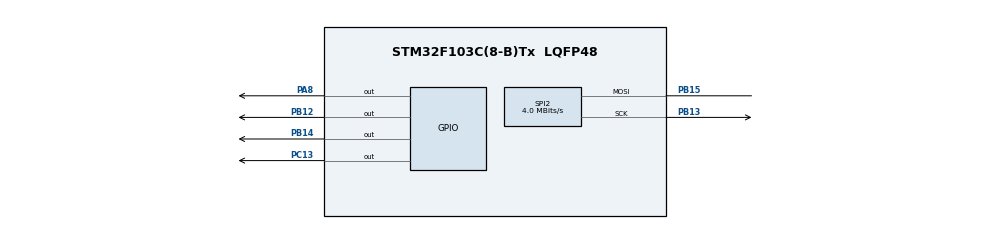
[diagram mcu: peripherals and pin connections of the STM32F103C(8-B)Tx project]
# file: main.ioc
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Mcu.Family=STM32F1
Mcu.Name=STM32F103C(8-B)Tx
Mcu.Package=LQFP48
NVIC.PriorityGroup=NVIC_PRIORITYGROUP_4
PA13.Mode=Serial_Wire
PA13.Signal=SYS_JTMS-SWDIO
PA14.Mode=Serial_Wire
PA14.Signal=SYS_JTCK-SWCLK
PA8.Signal=GPIO_Output
PB12.Signal=GPIO_Output
PB13.Mode=Simplex_Bidirectional_Master
PB13.Signal=SPI2_SCK
PB14.Signal=GPIO_Output
PB15.Mode=Simplex_Bidirectional_Master
PB15.Signal=SPI2_MOSI
PC13-TAMPER-RTC.Signal=GPIO_Output
ProjectManager.HeapSize=0x200
ProjectManager.StackSize=0x400
ProjectManager.TargetToolchain=Makefile
RCC.APB1Freq_Value=8000000
RCC.APB2Freq_Value=8000000
SPI2.BaudRatePrescaler=SPI_BAUDRATEPRESCALER_2
SPI2.CalculateBaudRate=4.0 MBits/s
SPI2.Direction=SPI_DIRECTION_1LINE
SPI2.Mode=SPI_MODE_MASTER
SPI2.VirtualType=VM_MASTER
board=main

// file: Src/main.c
#include "main.h"
#include "stm32f1xx_hal.h"

/* USER CODE BEGIN Includes */
#include "ssd1306_tests.h"
#include "ssd1306.h"
/* USER CODE END Includes */

SPI_HandleTypeDef hspi2;

/* USER CODE BEGIN PV */
/* Private variables ---------------------------------------------------------*/

/* USER CODE END PV */

void SystemClock_Config(void);
static void MX_GPIO_Init(void);
static void MX_SPI2_Init(void);

/* USER CODE BEGIN PFP */
/* Private function prototypes -----------------------------------------------*/

/* USER CODE END PFP */

/* USER CODE BEGIN 0 */
void init() {
    ssd1306_TestAll();

/*
    HAL_Delay(3000);

    for(uint8_t y = 0; y < 64; y++) {
        if(!(y&1)) { continue; }

        for(uint8_t x = 0; x < 128; x++) {
          ssd1306_DrawPixel(x, y, White);
        }
    }

    for(uint8_t x = 0; x < 128; x++) {
        if(!(x&1)) { continue; }

        for(uint8_t y = 0; y < 64; y++) {
          ssd1306_DrawPixel(x, y, White);
        }
    }

    ssd1306_UpdateScreen();
*/
}

void loop() {
    HAL_Delay(100);
}

/* USER CODE END 0 */

int main(void)
{

  /* MCU Configuration----------------------------------------------------------*/

  /* Reset of all peripherals, Initializes the Flash interface and the Systick. */
  HAL_Init();

  /* Configure the system clock */
  SystemClock_Config();

  /* Initialize all configured peripherals */
  MX_GPIO_Init();
  MX_SPI2_Init();

  /* Infinite loop */
  /* USER CODE BEGIN WHILE */
  init();
  while (1)
  {
    loop();
  /* USER CODE END WHILE */

  }

}

/** System Clock Configuration
*/
void SystemClock_Config(void)
{

  RCC_OscInitTypeDef RCC_OscInitStruct;
  RCC_ClkInitTypeDef RCC_ClkInitStruct;

    /**Initializes the CPU, AHB and APB busses clocks
    */
  RCC_OscInitStruct.OscillatorType = RCC_OSCILLATORTYPE_HSI;
  RCC_OscInitStruct.HSIState = RCC_HSI_ON;
  RCC_OscInitStruct.HSICalibrationValue = 16;
  RCC_OscInitStruct.PLL.PLLState = RCC_PLL_NONE;
  if (HAL_RCC_OscConfig(&RCC_OscInitStruct) != HAL_OK)
  {
    _Error_Handler(__FILE__, __LINE__);
  }

    /**Initializes the CPU, AHB and APB busses clocks
    */
  RCC_ClkInitStruct.ClockType = RCC_CLOCKTYPE_HCLK|RCC_CLOCKTYPE_SYSCLK
                              |RCC_CLOCKTYPE_PCLK1|RCC_CLOCKTYPE_PCLK2;
  RCC_ClkInitStruct.SYSCLKSource = RCC_SYSCLKSOURCE_HSI;
  RCC_ClkInitStruct.AHBCLKDivider = RCC_SYSCLK_DIV1;
  RCC_ClkInitStruct.APB1CLKDivider = RCC_HCLK_DIV1;
  RCC_ClkInitStruct.APB2CLKDivider = RCC_HCLK_DIV1;

  if (HAL_RCC_ClockConfig(&RCC_ClkInitStruct, FLASH_LATENCY_0) != HAL_OK)
  {
    _Error_Handler(__FILE__, __LINE__);
  }

    /**Configure the Systick interrupt time
    */
  HAL_SYSTICK_Config(HAL_RCC_GetHCLKFreq()/1000);

    /**Configure the Systick
    */
  HAL_SYSTICK_CLKSourceConfig(SYSTICK_CLKSOURCE_HCLK);

  /* SysTick_IRQn interrupt configuration */
  HAL_NVIC_SetPriority(SysTick_IRQn, 0, 0);
}

/* SPI2 init function */
static void MX_SPI2_Init(void)
{

  /* SPI2 parameter configuration*/
  hspi2.Instance = SPI2;
  hspi2.Init.Mode = SPI_MODE_MASTER;
  hspi2.Init.Direction = SPI_DIRECTION_1LINE;
  hspi2.Init.DataSize = SPI_DATASIZE_8BIT;
  hspi2.Init.CLKPolarity = SPI_POLARITY_LOW;
  hspi2.Init.CLKPhase = SPI_PHASE_1EDGE;
  hspi2.Init.NSS = SPI_NSS_SOFT;
  hspi2.Init.BaudRatePrescaler = SPI_BAUDRATEPRESCALER_2;
  hspi2.Init.FirstBit = SPI_FIRSTBIT_MSB;
  hspi2.Init.TIMode = SPI_TIMODE_DISABLE;
  hspi2.Init.CRCCalculation = SPI_CRCCALCULATION_DISABLE;
  hspi2.Init.CRCPolynomial = 10;
  if (HAL_SPI_Init(&hspi2) != HAL_OK)
  {
    _Error_Handler(__FILE__, __LINE__);
  }

}

/** Configure pins as
        * Analog
        * Input
        * Output
        * EVENT_OUT
        * EXTI
*/
static void MX_GPIO_Init(void)
{

  GPIO_InitTypeDef GPIO_InitStruct;

  /* GPIO Ports Clock Enable */
  __HAL_RCC_GPIOC_CLK_ENABLE();
  __HAL_RCC_GPIOB_CLK_ENABLE();
  __HAL_RCC_GPIOA_CLK_ENABLE();

  /*Configure GPIO pin Output Level */
  HAL_GPIO_WritePin(GPIOC, GPIO_PIN_13, GPIO_PIN_RESET);

  /*Configure GPIO pin Output Level */
  HAL_GPIO_WritePin(GPIOB, GPIO_PIN_12|GPIO_PIN_14, GPIO_PIN_RESET);

  /*Configure GPIO pin Output Level */
  HAL_GPIO_WritePin(GPIOA, GPIO_PIN_8, GPIO_PIN_RESET);

  /*Configure GPIO pin : PC13 */
  GPIO_InitStruct.Pin = GPIO_PIN_13;
  GPIO_InitStruct.Mode = GPIO_MODE_OUTPUT_PP;
  GPIO_InitStruct.Speed = GPIO_SPEED_FREQ_LOW;
  HAL_GPIO_Init(GPIOC, &GPIO_InitStruct);

  /*Configure GPIO pins : PB12 PB14 */
  GPIO_InitStruct.Pin = GPIO_PIN_12|GPIO_PIN_14;
  GPIO_InitStruct.Mode = GPIO_MODE_OUTPUT_PP;
  GPIO_InitStruct.Speed = GPIO_SPEED_FREQ_LOW;
  HAL_GPIO_Init(GPIOB, &GPIO_InitStruct);

  /*Configure GPIO pin : PA8 */
  GPIO_InitStruct.Pin = GPIO_PIN_8;
  GPIO_InitStruct.Mode = GPIO_MODE_OUTPUT_PP;
  GPIO_InitStruct.Speed = GPIO_SPEED_FREQ_LOW;
  HAL_GPIO_Init(GPIOA, &GPIO_InitStruct);

}

void _Error_Handler(char * file, int line)
{
  while(1)
  {
  }
}

/************************ (C) COPYRIGHT STMicroelectronics *****END OF FILE****/
